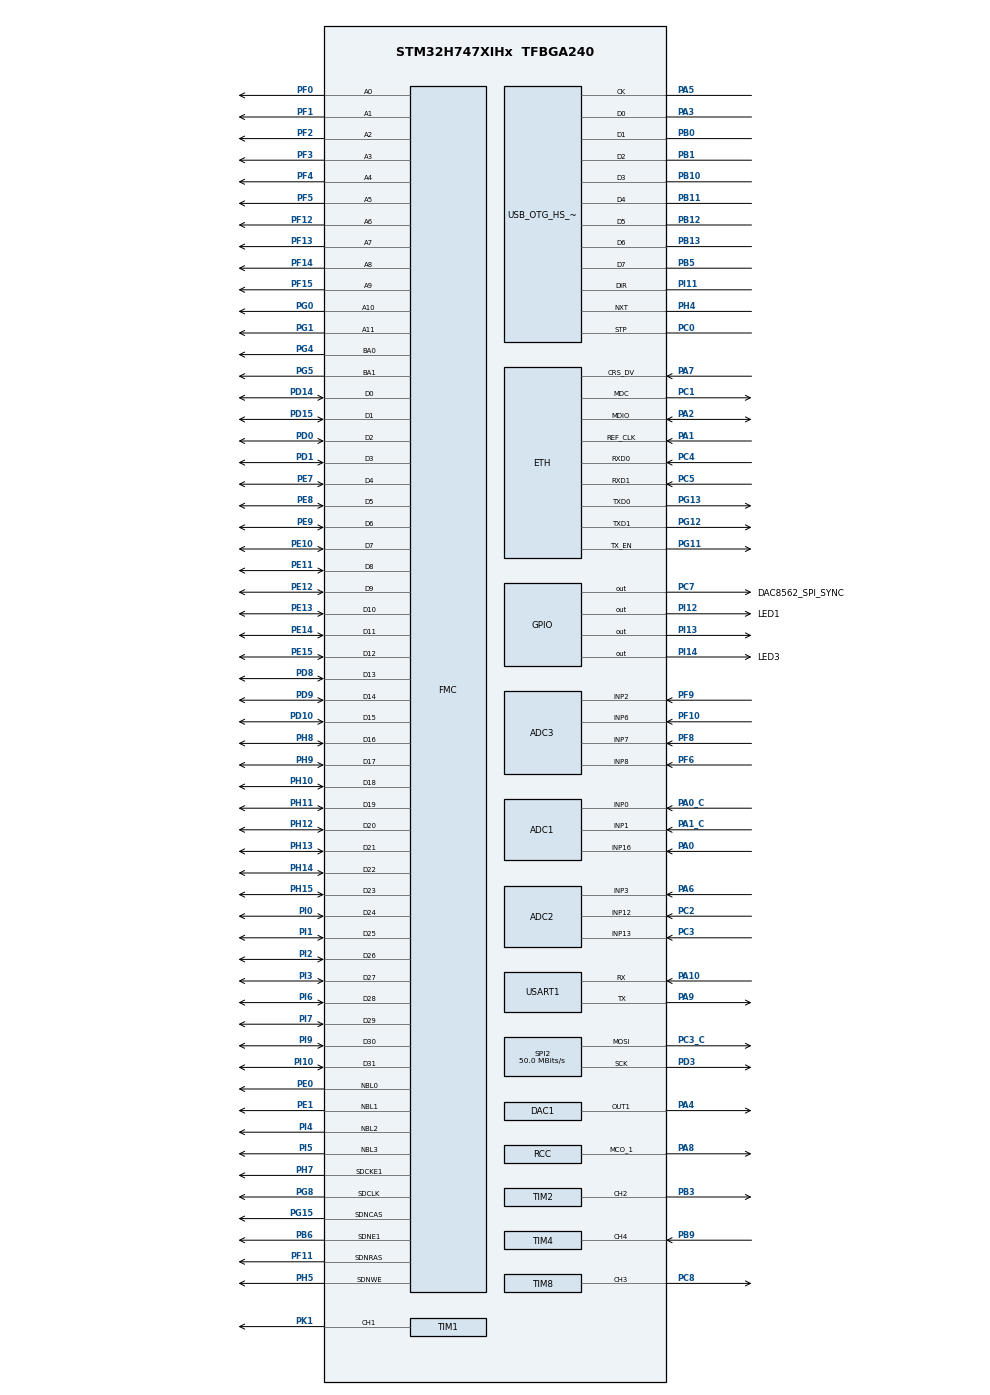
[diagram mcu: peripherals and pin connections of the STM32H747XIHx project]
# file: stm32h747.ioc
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ADC1.Channel-0\#ChannelRegularConversion=ADC_CHANNEL_0
ADC1.Channel-1\#ChannelRegularConversion=ADC_CHANNEL_1
ADC1.Channel-2\#ChannelRegularConversion=ADC_CHANNEL_16
ADC1.ClockPrescaler=ADC_CLOCK_ASYNC_DIV2
ADC1.ClockPrescalerADC3=ADC_CLOCK_ASYNC_DIV2
ADC1.ContinuousConvMode=DISABLE
ADC1.ConversionDataManagement=ADC_CONVERSIONDATA_DMA_CIRCULAR
ADC1.EOCSelection=ADC_EOC_SEQ_CONV
ADC1.ExternalTrigConv=ADC_EXTERNALTRIG_T15_TRGO
ADC1.NbrOfConversion=3
ADC1.NbrOfConversionFlag=1
ADC1.OffsetNumber-0\#ChannelRegularConversion=ADC_OFFSET_NONE
ADC1.OffsetNumber-1\#ChannelRegularConversion=ADC_OFFSET_NONE
ADC1.OffsetNumber-2\#ChannelRegularConversion=ADC_OFFSET_NONE
ADC1.OffsetSignedSaturation-0\#ChannelRegularConversion=DISABLE
ADC1.OffsetSignedSaturation-1\#ChannelRegularConversion=DISABLE
ADC1.OffsetSignedSaturation-2\#ChannelRegularConversion=DISABLE
ADC1.OversamplingMode=DISABLE
ADC1.Rank-0\#ChannelRegularConversion=1
ADC1.Rank-1\#ChannelRegularConversion=2
ADC1.Rank-2\#ChannelRegularConversion=3
ADC1.Ratio=1
ADC1.SamplingTime-0\#ChannelRegularConversion=ADC_SAMPLETIME_32CYCLES_5
ADC1.SamplingTime-1\#ChannelRegularConversion=ADC_SAMPLETIME_32CYCLES_5
ADC1.SamplingTime-2\#ChannelRegularConversion=ADC_SAMPLETIME_32CYCLES_5
ADC1.master=1
ADC2.Channel-0\#ChannelRegularConversion=ADC_CHANNEL_3
ADC2.Channel-1\#ChannelRegularConversion=ADC_CHANNEL_12
ADC2.Channel-2\#ChannelRegularConversion=ADC_CHANNEL_13
ADC2.ClockPrescaler=ADC_CLOCK_ASYNC_DIV2
ADC2.ClockPrescalerADC3=ADC_CLOCK_ASYNC_DIV2
ADC2.ContinuousConvMode=DISABLE
ADC2.ConversionDataManagement=ADC_CONVERSIONDATA_DMA_CIRCULAR
ADC2.EOCSelection=ADC_EOC_SEQ_CONV
ADC2.ExternalTrigConv=ADC_EXTERNALTRIG_T15_TRGO
ADC2.LeftBitShift=ADC_LEFTBITSHIFT_NONE
ADC2.NbrOfConversion=3
ADC2.NbrOfConversionFlag=1
ADC2.OffsetNumber-0\#ChannelRegularConversion=ADC_OFFSET_NONE
ADC2.OffsetNumber-1\#ChannelRegularConversion=ADC_OFFSET_NONE
ADC2.OffsetNumber-2\#ChannelRegularConversion=ADC_OFFSET_NONE
ADC2.OffsetSignedSaturation-0\#ChannelRegularConversion=DISABLE
ADC2.OffsetSignedSaturation-1\#ChannelRegularConversion=DISABLE
ADC2.OffsetSignedSaturation-2\#ChannelRegularConversion=DISABLE
ADC2.OversamplingMode=DISABLE
ADC2.Rank-0\#ChannelRegularConversion=1
ADC2.Rank-1\#ChannelRegularConversion=2
ADC2.Rank-2\#ChannelRegularConversion=3
ADC2.Ratio=1
ADC2.SamplingTime-0\#ChannelRegularConversion=ADC_SAMPLETIME_32CYCLES_5
ADC2.SamplingTime-1\#ChannelRegularConversion=ADC_SAMPLETIME_32CYCLES_5
ADC2.SamplingTime-2\#ChannelRegularConversion=ADC_SAMPLETIME_32CYCLES_5
ADC3.Channel-0\#ChannelRegularConversion=ADC_CHANNEL_2
ADC3.Channel-1\#ChannelRegularConversion=ADC_CHANNEL_6
ADC3.Channel-2\#ChannelRegularConversion=ADC_CHANNEL_7
ADC3.Channel-3\#ChannelRegularConversion=ADC_CHANNEL_8
ADC3.ClockPrescalerADC3=ADC_CLOCK_ASYNC_DIV2
ADC3.ContinuousConvMode=DISABLE
ADC3.ConversionDataManagement=ADC_CONVERSIONDATA_DMA_CIRCULAR
ADC3.EOCSelection=ADC_EOC_SEQ_CONV
ADC3.ExternalTrigConv=ADC_EXTERNALTRIG_T15_TRGO
ADC3.NbrOfConversion=4
ADC3.NbrOfConversionFlag=1
ADC3.OffsetNumber-0\#ChannelRegularConversion=ADC_OFFSET_NONE
ADC3.OffsetNumber-1\#ChannelRegularConversion=ADC_OFFSET_NONE
ADC3.OffsetNumber-2\#ChannelRegularConversion=ADC_OFFSET_NONE
ADC3.OffsetNumber-3\#ChannelRegularConversion=ADC_OFFSET_NONE
ADC3.OffsetSignedSaturation-0\#ChannelRegularConversion=DISABLE
ADC3.OffsetSignedSaturation-1\#ChannelRegularConversion=DISABLE
ADC3.OffsetSignedSaturation-2\#ChannelRegularConversion=DISABLE
ADC3.OffsetSignedSaturation-3\#ChannelRegularConversion=DISABLE
ADC3.OversamplingMode=DISABLE
ADC3.Rank-0\#ChannelRegularConversion=1
ADC3.Rank-1\#ChannelRegularConversion=2
ADC3.Rank-2\#ChannelRegularConversion=3
ADC3.Rank-3\#ChannelRegularConversion=4
ADC3.Ratio=1
ADC3.SamplingTime-0\#ChannelRegularConversion=ADC_SAMPLETIME_32CYCLES_5
ADC3.SamplingTime-1\#ChannelRegularConversion=ADC_SAMPLETIME_32CYCLES_5
ADC3.SamplingTime-2\#ChannelRegularConversion=ADC_SAMPLETIME_32CYCLES_5
ADC3.SamplingTime-3\#ChannelRegularConversion=ADC_SAMPLETIME_32CYCLES_5
CORTEX_M4.MPU_Control=__NULL
CORTEX_M7.AccessPermission-Cortex_Memory_Protection_Unit_Region1_Settings=MPU_REGION_FULL_ACCESS
CORTEX_M7.AccessPermission-Cortex_Memory_Protection_Unit_Region2_Settings=MPU_REGION_FULL_ACCESS
CORTEX_M7.AccessPermission-Cortex_Memory_Protection_Unit_Region3_Settings=MPU_REGION_FULL_ACCESS
CORTEX_M7.AccessPermission-Cortex_Memory_Protection_Unit_Region4_Settings=MPU_REGION_FULL_ACCESS
CORTEX_M7.BaseAddress-Cortex_Memory_Protection_Unit_Region0_Settings=0x0
CORTEX_M7.BaseAddress-Cortex_Memory_Protection_Unit_Region1_Settings=0x030000600
CORTEX_M7.BaseAddress-Cortex_Memory_Protection_Unit_Region2_Settings=0x30000000
CORTEX_M7.BaseAddress-Cortex_Memory_Protection_Unit_Region3_Settings=0x38000000
CORTEX_M7.BaseAddress-Cortex_Memory_Protection_Unit_Region4_Settings=0xD0000000
CORTEX_M7.CPU_DCache=Enabled
CORTEX_M7.CPU_ICache=Enabled
CORTEX_M7.DisableExec-Cortex_Memory_Protection_Unit_Region0_Settings=MPU_INSTRUCTION_ACCESS_DISABLE
CORTEX_M7.DisableExec-Cortex_Memory_Protection_Unit_Region1_Settings=MPU_INSTRUCTION_ACCESS_DISABLE
CORTEX_M7.DisableExec-Cortex_Memory_Protection_Unit_Region2_Settings=MPU_INSTRUCTION_ACCESS_DISABLE
CORTEX_M7.Enable-Cortex_Memory_Protection_Unit_Region0_Settings=MPU_REGION_ENABLE
CORTEX_M7.Enable-Cortex_Memory_Protection_Unit_Region1_Settings=MPU_REGION_ENABLE
CORTEX_M7.Enable-Cortex_Memory_Protection_Unit_Region2_Settings=MPU_REGION_ENABLE
CORTEX_M7.Enable-Cortex_Memory_Protection_Unit_Region3_Settings=MPU_REGION_ENABLE
CORTEX_M7.Enable-Cortex_Memory_Protection_Unit_Region4_Settings=MPU_REGION_ENABLE
CORTEX_M7.IsBufferable-Cortex_Memory_Protection_Unit_Region2_Settings=MPU_ACCESS_BUFFERABLE
CORTEX_M7.IsBufferable-Cortex_Memory_Protection_Unit_Region4_Settings=MPU_ACCESS_BUFFERABLE
CORTEX_M7.IsCacheable-Cortex_Memory_Protection_Unit_Region4_Settings=MPU_ACCESS_CACHEABLE
CORTEX_M7.IsShareable-Cortex_Memory_Protection_Unit_Region0_Settings=MPU_ACCESS_SHAREABLE
CORTEX_M7.IsShareable-Cortex_Memory_Protection_Unit_Region2_Settings=MPU_ACCESS_SHAREABLE
CORTEX_M7.IsShareable-Cortex_Memory_Protection_Unit_Region3_Settings=MPU_ACCESS_SHAREABLE
CORTEX_M7.IsShareable-Cortex_Memory_Protection_Unit_Region4_Settings=MPU_ACCESS_NOT_SHAREABLE
CORTEX_M7.MPU_Control=MPU_PRIVILEGED_DEFAULT
CORTEX_M7.Size-Cortex_Memory_Protection_Unit_Region0_Settings=MPU_REGION_SIZE_4GB
CORTEX_M7.Size-Cortex_Memory_Protection_Unit_Region1_Settings=MPU_REGION_SIZE_128KB
CORTEX_M7.Size-Cortex_Memory_Protection_Unit_Region2_Settings=MPU_REGION_SIZE_512B
CORTEX_M7.Size-Cortex_Memory_Protection_Unit_Region3_Settings=MPU_REGION_SIZE_64KB
CORTEX_M7.Size-Cortex_Memory_Protection_Unit_Region4_Settings=MPU_REGION_SIZE_32MB
CORTEX_M7.SubRegionDisable-Cortex_Memory_Protection_Unit_Region0_Settings=0x87
CORTEX_M7.TypeExtField-Cortex_Memory_Protection_Unit_Region1_Settings=MPU_TEX_LEVEL1
CORTEX_M7.default_mode_Activation=0
CortexM4.IPs=CORTEX_M4\:I,FATFS_M4\:I,FREERTOS_M4\:I,IWDG2\:I,OPENAMP_M4\:I,PDM2PCM_M4\:I,PWR,RCC,RESMGR_UTILITY,SYS_M4\:I,USB_DEVICE_M4\:I,USB_HOST_M4\:I,VREFBUF,WWDG2\:I,GPIO,DMA,BDMA,MDMA,NVIC2\:I,DEBUG
CortexM7.IPs=CORTEX_M7\:I,FATFS_M7\:I,FREERTOS_M7\:I,IWDG1\:I,OPENAMP_M7\:I,PDM2PCM_M7\:I,PWR\:I,RCC\:I,RESMGR_UTILITY\:I,SYS\:I,USB_DEVICE_M7\:I,USB_HOST_M7\:I,VREFBUF\:I,WWDG1\:I,GPIO\:I,DMA\:I,BDMA\:I,MDMA\:I,NVIC1\:I,ADC1\:I,ADC2\:I,ADC3\:I,TIM1\:I,TIM2\:I,DEBUG\:I,TIM6\:I,ETH\:I,USART1\:I,USB_OTG_HS\:I,USB_OTG_HS1\:I,FMC\:I,DAC1\:I,LWIP\:I,MEMORYMAP\:I,TIM3\:I,TIM15\:I,TIM4\:I,TIM8\:I,SPI2\:I
CortexM7.Pins=PC7,PI12,PI13,PI14
DAC1.DAC_Channel-DAC_OUT1=DAC_CHANNEL_1
Dma.ADC1.0.Direction=DMA_PERIPH_TO_MEMORY
Dma.ADC1.0.EventEnable=DISABLE
Dma.ADC1.0.FIFOMode=DMA_FIFOMODE_DISABLE
Dma.ADC1.0.Instance=DMA1_Stream0
Dma.ADC1.0.MemDataAlignment=DMA_MDATAALIGN_HALFWORD
Dma.ADC1.0.MemInc=DMA_MINC_ENABLE
Dma.ADC1.0.Mode=DMA_CIRCULAR
Dma.ADC1.0.PeriphDataAlignment=DMA_PDATAALIGN_HALFWORD
Dma.ADC1.0.PeriphInc=DMA_PINC_DISABLE
Dma.ADC1.0.Polarity=HAL_DMAMUX_REQ_GEN_RISING
Dma.ADC1.0.Priority=DMA_PRIORITY_LOW
Dma.ADC1.0.RequestNumber=1
Dma.ADC1.0.SignalID=NONE
Dma.ADC1.0.SyncEnable=DISABLE
Dma.ADC1.0.SyncPolarity=HAL_DMAMUX_SYNC_NO_EVENT
Dma.ADC1.0.SyncRequestNumber=1
Dma.ADC1.0.SyncSignalID=NONE
Dma.ADC2.1.Direction=DMA_PERIPH_TO_MEMORY
Dma.ADC2.1.EventEnable=DISABLE
Dma.ADC2.1.FIFOMode=DMA_FIFOMODE_DISABLE
Dma.ADC2.1.Instance=DMA2_Stream2
Dma.ADC2.1.MemDataAlignment=DMA_MDATAALIGN_HALFWORD
Dma.ADC2.1.MemInc=DMA_MINC_ENABLE
Dma.ADC2.1.Mode=DMA_CIRCULAR
Dma.ADC2.1.PeriphDataAlignment=DMA_PDATAALIGN_HALFWORD
Dma.ADC2.1.PeriphInc=DMA_PINC_DISABLE
Dma.ADC2.1.Polarity=HAL_DMAMUX_REQ_GEN_RISING
Dma.ADC2.1.Priority=DMA_PRIORITY_LOW
Dma.ADC2.1.RequestNumber=1
Dma.ADC2.1.SignalID=NONE
Dma.ADC2.1.SyncEnable=DISABLE
Dma.ADC2.1.SyncPolarity=HAL_DMAMUX_SYNC_NO_EVENT
Dma.ADC2.1.SyncRequestNumber=1
Dma.ADC2.1.SyncSignalID=NONE
Dma.ADC3.2.Direction=DMA_PERIPH_TO_MEMORY
Dma.ADC3.2.EventEnable=DISABLE
Dma.ADC3.2.FIFOMode=DMA_FIFOMODE_DISABLE
Dma.ADC3.2.Instance=DMA1_Stream2
Dma.ADC3.2.MemDataAlignment=DMA_MDATAALIGN_HALFWORD
Dma.ADC3.2.MemInc=DMA_MINC_ENABLE
Dma.ADC3.2.Mode=DMA_CIRCULAR
Dma.ADC3.2.PeriphDataAlignment=DMA_PDATAALIGN_HALFWORD
Dma.ADC3.2.PeriphInc=DMA_PINC_DISABLE
Dma.ADC3.2.Polarity=HAL_DMAMUX_REQ_GEN_RISING
Dma.ADC3.2.Priority=DMA_PRIORITY_LOW
Dma.ADC3.2.RequestNumber=1
Dma.ADC3.2.SignalID=NONE
Dma.ADC3.2.SyncEnable=DISABLE
Dma.ADC3.2.SyncPolarity=HAL_DMAMUX_SYNC_NO_EVENT
Dma.ADC3.2.SyncRequestNumber=1
Dma.ADC3.2.SyncSignalID=NONE
Dma.Request0=ADC1
Dma.Request1=ADC2
Dma.Request2=ADC3
Dma.Request3=USART1_RX
Dma.Request4=SPI2_TX
Dma.SPI2_TX.4.Direction=DMA_MEMORY_TO_PERIPH
Dma.SPI2_TX.4.EventEnable=DISABLE
Dma.SPI2_TX.4.FIFOMode=DMA_FIFOMODE_DISABLE
Dma.SPI2_TX.4.Instance=DMA1_Stream3
Dma.SPI2_TX.4.MemDataAlignment=DMA_MDATAALIGN_BYTE
Dma.SPI2_TX.4.MemInc=DMA_MINC_ENABLE
Dma.SPI2_TX.4.Mode=DMA_NORMAL
Dma.SPI2_TX.4.PeriphDataAlignment=DMA_PDATAALIGN_BYTE
Dma.SPI2_TX.4.PeriphInc=DMA_PINC_DISABLE
Dma.SPI2_TX.4.Polarity=HAL_DMAMUX_REQ_GEN_RISING
Dma.SPI2_TX.4.Priority=DMA_PRIORITY_LOW
Dma.SPI2_TX.4.RequestNumber=1
Dma.SPI2_TX.4.SignalID=NONE
Dma.SPI2_TX.4.SyncEnable=DISABLE
Dma.SPI2_TX.4.SyncPolarity=HAL_DMAMUX_SYNC_NO_EVENT
Dma.SPI2_TX.4.SyncRequestNumber=1
Dma.SPI2_TX.4.SyncSignalID=NONE
Dma.USART1_RX.3.Direction=DMA_PERIPH_TO_MEMORY
Dma.USART1_RX.3.EventEnable=DISABLE
Dma.USART1_RX.3.FIFOMode=DMA_FIFOMODE_DISABLE
Dma.USART1_RX.3.Instance=DMA1_Stream1
Dma.USART1_RX.3.MemDataAlignment=DMA_MDATAALIGN_BYTE
Dma.USART1_RX.3.MemInc=DMA_MINC_ENABLE
Dma.USART1_RX.3.Mode=DMA_NORMAL
Dma.USART1_RX.3.PeriphDataAlignment=DMA_PDATAALIGN_BYTE
Dma.USART1_RX.3.PeriphInc=DMA_PINC_DISABLE
Dma.USART1_RX.3.Polarity=HAL_DMAMUX_REQ_GEN_RISING
Dma.USART1_RX.3.Priority=DMA_PRIORITY_LOW
Dma.USART1_RX.3.RequestNumber=1
Dma.USART1_RX.3.SignalID=NONE
Dma.USART1_RX.3.SyncEnable=DISABLE
Dma.USART1_RX.3.SyncPolarity=HAL_DMAMUX_SYNC_NO_EVENT
Dma.USART1_RX.3.SyncRequestNumber=1
Dma.USART1_RX.3.SyncSignalID=NONE
ETH.MediaInterface=HAL_ETH_RMII_MODE
ETH.RxBufferAddress=0x30000200
ETH.RxDescAddress=0x30000000
ETH.TxDescAddress=0x30000100
FMC.CASLatency1=FMC_SDRAM_CAS_LATENCY_3
FMC.ColumnBitsNumber1=FMC_SDRAM_COLUMN_BITS_NUM_9
FMC.ExitSelfRefreshDelay1=7
FMC.LoadToActiveDelay1=2
FMC.RCDDelay1=2
FMC.RPDelay1=2
FMC.RPDelay2=2
FMC.ReadBurst1=FMC_SDRAM_RBURST_ENABLE
FMC.ReadBurst2=FMC_SDRAM_RBURST_ENABLE
FMC.RowCycleDelay1=6
FMC.RowCycleDelay2=6
FMC.SDClockPeriod1=FMC_SDRAM_CLOCK_PERIOD_2
FMC.SDClockPeriod2=FMC_SDRAM_CLOCK_PERIOD_2
FMC.SelfRefreshTime1=4
FMC.WriteRecoveryTime1=2
FREERTOS_M7.Tasks01=defaultTask,24,512,StartDefaultTask,Default,NULL,Dynamic,NULL,NULL
FREERTOS_M7.configCHECK_FOR_STACK_OVERFLOW=2
FREERTOS_M7.configENABLE_FPU=1
FREERTOS_M7.configMINIMAL_STACK_SIZE=512
FREERTOS_M7.configTOTAL_HEAP_SIZE=32768
FREERTOS_M7.configUSE_NEWLIB_REENTRANT=1
LWIP.BSP.number=1
LWIP.DEFAULT_THREAD_PRIO=32
LWIP.DEFAULT_THREAD_STACKSIZE=2048
LWIP.LWIP_NETIF_STATUS_CALLBACK=0
LWIP.LWIP_RAM_HEAP_POINTER=0x30000600
LWIP.LWIP_SO_RCVBUF=1
LWIP.MEMP_NUM_LOCALHOSTLIST=0
LWIP.MEMP_NUM_PBUF=24
LWIP.MEMP_NUM_TCP_PCB_LISTEN=4
LWIP.MEMP_NUM_TCP_SEG=32
LWIP.MEM_SIZE=48 * 1024
LWIP.PBUF_POOL_BUFSIZE=1536
LWIP.SO_REUSE=1
LWIP.TCPIP_THREAD_PRIO=32
LWIP.TCPIP_THREAD_STACKSIZE=2048
LWIP.TCP_LISTEN_BACKLOG=1
LWIP.TCP_MSS=1460
LWIP.TCP_SND_BUF=5840
LWIP.TCP_SND_QUEUELEN=16
LWIP.TCP_WND=5840
LWIP.Version=v2.2.1_Cube
LWIP0.BSP.STBoard=false
LWIP0.BSP.api=BSP_COMPONENT_DRIVER
LWIP0.BSP.component=LAN8742
LWIP0.BSP.instance=LAN8742
LWIP0.BSP.name=Driver_PHY
LWIP0.BSP.semaphore=S_LAN8742
LWIP0.BSP.solution=LAN8742
Mcu.Family=STM32H7
Mcu.Name=STM32H747XIHx
Mcu.Package=TFBGA240
NVIC1.DMA1_Stream0_IRQn=true\:5\:0\:false\:false\:true\:true\:false\:true\:true
NVIC1.DMA1_Stream1_IRQn=true\:5\:0\:false\:false\:true\:true\:false\:true\:true
NVIC1.DMA1_Stream2_IRQn=true\:5\:0\:false\:false\:true\:true\:false\:true\:true
NVIC1.DMA1_Stream3_IRQn=true\:5\:0\:false\:false\:true\:true\:false\:true\:true
NVIC1.DMA2_Stream2_IRQn=true\:5\:0\:false\:false\:true\:true\:false\:true\:true
NVIC1.ETH_IRQn=true\:5\:0\:false\:false\:true\:true\:true\:true\:true
NVIC1.OTG_HS_IRQn=true\:5\:0\:false\:false\:true\:true\:true\:true\:true
NVIC1.PriorityGroup=NVIC_PRIORITYGROUP_4
NVIC1.SPI2_IRQn=true\:5\:0\:false\:false\:true\:true\:false\:true\:true
NVIC1.TIM2_IRQn=true\:5\:0\:false\:false\:true\:true\:true\:true\:true
NVIC1.TIM3_IRQn=true\:5\:0\:false\:false\:true\:true\:true\:true\:true
NVIC1.TIM6_DAC_IRQn=true\:15\:0\:false\:false\:true\:false\:false\:true\:true
NVIC1.TimeBase=TIM6_DAC_IRQn
NVIC1.TimeBaseIP=TIM6
NVIC2.PriorityGroup=NVIC_PRIORITYGROUP_4
PA0.Mode=IN16-Single-Ended
PA0.PinAttribute=CortexM7
PA0.Signal=ADC1_INP16
PA0_C.PinAttribute=CortexM7
PA0_C.Signal=ADCx_INP0
PA1.GPIO_Speed_Default_HIGH=GPIO_SPEED_FREQ_VERY_HIGH
PA1.Mode=RMII
PA1.PinAttribute=CortexM7
PA1.Signal=ETH_REF_CLK
PA10.GPIO_Speed=GPIO_SPEED_FREQ_VERY_HIGH
PA10.Mode=Asynchronous
PA10.PinAttribute=CortexM7
PA10.Signal=USART1_RX
PA13\ (JTMS/SWDIO).Mode=Serial_Wire
PA13\ (JTMS/SWDIO).PinAttribute=CortexM7
PA13\ (JTMS/SWDIO).Signal=DEBUG_JTMS-SWDIO
PA14\ (JTCK/SWCLK).Mode=Serial_Wire
PA14\ (JTCK/SWCLK).PinAttribute=CortexM7
PA14\ (JTCK/SWCLK).Signal=DEBUG_JTCK-SWCLK
PA1_C.PinAttribute=CortexM7
PA1_C.Signal=ADCx_INP1
PA2.GPIO_Speed_Default_HIGH=GPIO_SPEED_FREQ_VERY_HIGH
PA2.Mode=RMII
PA2.PinAttribute=CortexM7
PA2.Signal=ETH_MDIO
PA3.Mode=Device_HS
PA3.PinAttribute=CortexM7
PA3.Signal=USB_OTG_HS_ULPI_D0
PA4.PinAttribute=CortexM7
PA4.Signal=COMP_DAC11_group
PA5.Mode=Device_HS
PA5.PinAttribute=CortexM7
PA5.Signal=USB_OTG_HS_ULPI_CK
PA6.PinAttribute=CortexM7
PA6.Signal=ADCx_INP3
PA7.GPIO_Speed_Default_HIGH=GPIO_SPEED_FREQ_VERY_HIGH
PA7.Mode=RMII
PA7.PinAttribute=CortexM7
PA7.Signal=ETH_CRS_DV
PA8.Mode=Clock-out-1
PA8.PinAttribute=Free
PA8.Signal=RCC_MCO_1
PA9.GPIO_Speed=GPIO_SPEED_FREQ_VERY_HIGH
PA9.Mode=Asynchronous
PA9.PinAttribute=CortexM7
PA9.Signal=USART1_TX
PB0.Mode=Device_HS
PB0.PinAttribute=CortexM7
PB0.Signal=USB_OTG_HS_ULPI_D1
PB1.Mode=Device_HS
PB1.PinAttribute=CortexM7
PB1.Signal=USB_OTG_HS_ULPI_D2
PB10.Mode=Device_HS
PB10.PinAttribute=CortexM7
PB10.Signal=USB_OTG_HS_ULPI_D3
PB11.Mode=Device_HS
PB11.PinAttribute=CortexM7
PB11.Signal=USB_OTG_HS_ULPI_D4
PB12.Mode=Device_HS
PB12.PinAttribute=CortexM7
PB12.Signal=USB_OTG_HS_ULPI_D5
PB13.Mode=Device_HS
PB13.PinAttribute=CortexM7
PB13.Signal=USB_OTG_HS_ULPI_D6
PB3\ (JTDO/TRACESWO).PinAttribute=CortexM7
PB3\ (JTDO/TRACESWO).Signal=S_TIM2_CH2
PB5.Mode=Device_HS
PB5.PinAttribute=CortexM7
PB5.Signal=USB_OTG_HS_ULPI_D7
PB6.Mode=SdramChipSelect2_1
PB6.PinAttribute=CortexM7
PB6.Signal=FMC_SDNE1
PB9.PinAttribute=CortexM7
PB9.Signal=S_TIM4_CH4
PC0.Mode=Device_HS
PC0.PinAttribute=CortexM7
PC0.Signal=USB_OTG_HS_ULPI_STP
PC1.GPIO_Speed_Default_HIGH=GPIO_SPEED_FREQ_VERY_HIGH
PC1.Mode=RMII
PC1.PinAttribute=CortexM7
PC1.Signal=ETH_MDC
PC2.PinAttribute=CortexM7
PC2.Signal=ADCx_INP12
PC3.PinAttribute=CortexM7
PC3.Signal=ADCx_INP13
PC3_C.GPIO_Speed=GPIO_SPEED_FREQ_VERY_HIGH
PC3_C.Mode=TX_Only_Simplex_Unidirect_Master
PC3_C.PinAttribute=CortexM7
PC3_C.Signal=SPI2_MOSI
PC4.GPIO_Speed_Default_HIGH=GPIO_SPEED_FREQ_VERY_HIGH
PC4.Mode=RMII
PC4.PinAttribute=CortexM7
PC4.Signal=ETH_RXD0
PC5.GPIO_Speed_Default_HIGH=GPIO_SPEED_FREQ_VERY_HIGH
PC5.Mode=RMII
PC5.PinAttribute=CortexM7
PC5.Signal=ETH_RXD1
PC7.GPIO_Label=DAC8562_SPI_SYNC
PC7.GPIO_Speed=GPIO_SPEED_FREQ_VERY_HIGH
PC7.PinAttribute=CortexM7
PC7.Signal=GPIO_Output
PC8.PinAttribute=CortexM7
PC8.Signal=S_TIM8_CH3
PD0.PinAttribute=CortexM7
PD0.Signal=FMC_D2_DA2
PD1.PinAttribute=CortexM7
PD1.Signal=FMC_D3_DA3
PD10.PinAttribute=CortexM7
PD10.Signal=FMC_D15_DA15
PD14.PinAttribute=CortexM7
PD14.Signal=FMC_D0_DA0
PD15.PinAttribute=CortexM7
PD15.Signal=FMC_D1_DA1
PD3.GPIO_Speed=GPIO_SPEED_FREQ_VERY_HIGH
PD3.Mode=TX_Only_Simplex_Unidirect_Master
PD3.PinAttribute=CortexM7
PD3.Signal=SPI2_SCK
PD8.PinAttribute=CortexM7
PD8.Signal=FMC_D13_DA13
PD9.PinAttribute=CortexM7
PD9.Signal=FMC_D14_DA14
PE0.PinAttribute=CortexM7
PE0.Signal=FMC_NBL0
PE1.PinAttribute=CortexM7
PE1.Signal=FMC_NBL1
PE10.PinAttribute=CortexM7
PE10.Signal=FMC_D7_DA7
PE11.PinAttribute=CortexM7
PE11.Signal=FMC_D8_DA8
PE12.PinAttribute=CortexM7
PE12.Signal=FMC_D9_DA9
PE13.PinAttribute=CortexM7
PE13.Signal=FMC_D10_DA10
PE14.PinAttribute=CortexM7
PE14.Signal=FMC_D11_DA11
PE15.PinAttribute=CortexM7
PE15.Signal=FMC_D12_DA12
PE7.PinAttribute=CortexM7
PE7.Signal=FMC_D4_DA4
PE8.PinAttribute=CortexM7
PE8.Signal=FMC_D5_DA5
PE9.PinAttribute=CortexM7
PE9.Signal=FMC_D6_DA6
PF0.PinAttribute=CortexM7
PF0.Signal=FMC_A0
PF1.PinAttribute=CortexM7
PF1.Signal=FMC_A1
PF10.Mode=IN6-Single-Ended
PF10.PinAttribute=CortexM7
PF10.Signal=ADC3_INP6
PF11.PinAttribute=CortexM7
PF11.Signal=FMC_SDNRAS
PF12.PinAttribute=CortexM7
PF12.Signal=FMC_A6
PF13.PinAttribute=CortexM7
PF13.Signal=FMC_A7
PF14.PinAttribute=CortexM7
PF14.Signal=FMC_A8
PF15.PinAttribute=CortexM7
PF15.Signal=FMC_A9
PF2.PinAttribute=CortexM7
PF2.Signal=FMC_A2
PF3.PinAttribute=CortexM7
PF3.Signal=FMC_A3
PF4.PinAttribute=CortexM7
PF4.Signal=FMC_A4
PF5.PinAttribute=CortexM7
PF5.Signal=FMC_A5
PF6.Mode=IN8-Single-Ended
PF6.PinAttribute=CortexM7
PF6.Signal=ADC3_INP8
PF8.Mode=IN7-Single-Ended
PF8.PinAttribute=CortexM7
PF8.Signal=ADC3_INP7
PF9.Mode=IN2-Single-Ended
PF9.PinAttribute=CortexM7
PF9.Signal=ADC3_INP2
PG0.PinAttribute=CortexM7
PG0.Signal=FMC_A10
PG1.PinAttribute=CortexM7
PG1.Signal=FMC_A11
PG11.GPIO_Speed_Default_HIGH=GPIO_SPEED_FREQ_VERY_HIGH
PG11.Mode=RMII
PG11.PinAttribute=CortexM7
PG11.Signal=ETH_TX_EN
PG12.GPIO_Speed_Default_HIGH=GPIO_SPEED_FREQ_VERY_HIGH
PG12.Mode=RMII
PG12.PinAttribute=CortexM7
PG12.Signal=ETH_TXD1
PG13.GPIO_Speed_Default_HIGH=GPIO_SPEED_FREQ_VERY_HIGH
PG13.Mode=RMII
PG13.PinAttribute=CortexM7
PG13.Signal=ETH_TXD0
PG15.PinAttribute=CortexM7
PG15.Signal=FMC_SDNCAS
PG4.PinAttribute=CortexM7
PG4.Signal=FMC_A14_BA0
PG5.PinAttribute=CortexM7
PG5.Signal=FMC_A15_BA1
PG8.PinAttribute=CortexM7
PG8.Signal=FMC_SDCLK
PH0-OSC_IN\ (PH0).Mode=HSE-External-Oscillator
PH0-OSC_IN\ (PH0).PinAttribute=Free
PH0-OSC_IN\ (PH0).Signal=RCC_OSC_IN
PH1-OSC_OUT\ (PH1).Mode=HSE-External-Oscillator
PH1-OSC_OUT\ (PH1).PinAttribute=Free
PH1-OSC_OUT\ (PH1).Signal=RCC_OSC_OUT
PH10.PinAttribute=CortexM7
PH10.Signal=FMC_D18
PH11.PinAttribute=CortexM7
PH11.Signal=FMC_D19
PH12.PinAttribute=CortexM7
PH12.Signal=FMC_D20
PH13.PinAttribute=CortexM7
PH13.Signal=FMC_D21
PH14.PinAttribute=CortexM7
PH14.Signal=FMC_D22
PH15.PinAttribute=CortexM7
PH15.Signal=FMC_D23
PH4.Mode=Device_HS
PH4.PinAttribute=CortexM7
PH4.Signal=USB_OTG_HS_ULPI_NXT
PH5.PinAttribute=CortexM7
PH5.Signal=FMC_SDNWE
PH7.Mode=SdramChipSelect2_1
PH7.PinAttribute=CortexM7
PH7.Signal=FMC_SDCKE1
PH8.PinAttribute=CortexM7
PH8.Signal=FMC_D16
PH9.PinAttribute=CortexM7
PH9.Signal=FMC_D17
PI0.PinAttribute=CortexM7
PI0.Signal=FMC_D24
PI1.PinAttribute=CortexM7
PI1.Signal=FMC_D25
PI10.PinAttribute=CortexM7
PI10.Signal=FMC_D31
PI11.Mode=Device_HS
PI11.PinAttribute=CortexM7
PI11.Signal=USB_OTG_HS_ULPI_DIR
PI12.GPIO_Label=LED1
PI12.PinAttribute=CortexM7
PI12.Signal=GPIO_Output
PI13.PinAttribute=CortexM7
PI13.Signal=GPIO_Output
PI14.GPIO_Label=LED3
PI14.PinAttribute=CortexM7
PI14.Signal=GPIO_Output
PI2.PinAttribute=CortexM7
PI2.Signal=FMC_D26
PI3.PinAttribute=CortexM7
PI3.Signal=FMC_D27
PI4.PinAttribute=CortexM7
PI4.Signal=FMC_NBL2
PI5.PinAttribute=CortexM7
PI5.Signal=FMC_NBL3
PI6.PinAttribute=CortexM7
PI6.Signal=FMC_D28
PI7.PinAttribute=CortexM7
PI7.Signal=FMC_D29
PI9.PinAttribute=CortexM7
PI9.Signal=FMC_D30
PK1.GPIO_Speed=GPIO_SPEED_FREQ_VERY_HIGH
PK1.PinAttribute=CortexM7
PK1.Signal=S_TIM1_CH1
ProjectManager.HeapSize=M4-0x200,M7-0x200
ProjectManager.StackSize=M4-0x1000,M7-0x1000
ProjectManager.TargetToolchain=CMake
RCC.ADCCLockSelection=RCC_ADCCLKSOURCE_PLL3
RCC.ADCFreq_Value=100000000
RCC.APB1Freq_Value=100000000
RCC.APB2Freq_Value=100000000
RCC.APB3Freq_Value=100000000
RCC.APB4Freq_Value=100000000
RCC.CortexFreq_Value=400000000
RCC.D1PPRE=RCC_APB3_DIV2
RCC.D2PPRE1=RCC_APB1_DIV2
RCC.D2PPRE2=RCC_APB2_DIV2
RCC.D3PPRE=RCC_APB4_DIV2
RCC.DIVM1=2
RCC.DIVM2=25
RCC.DIVM3=2
RCC.DIVN1=64
RCC.DIVN2=150
RCC.DIVN3=32
RCC.DIVQ3=4
RCC.DIVR3=4
RCC.HCLKFreq_Value=200000000
RCC.HPRE=RCC_HCLK_DIV2
RCC.PLL2_VCO_SEL-AdvancedSettings=RCC_PLL2VCOWIDE
RCC.PLL3FRACN=0
RCC.PLLFRACN=0
RCC.PLLSourceVirtual=RCC_PLLSOURCE_HSE
RCC.SPI123CLockSelection=RCC_SPI123CLKSOURCE_PLL3
RCC.SYSCLKFreq_VALUE=400000000
RCC.SYSCLKSource=RCC_SYSCLKSOURCE_PLLCLK
RCC.Spi45ClockSelection=RCC_SPI45CLKSOURCE_PLL3
RCC.SupplySource=PWR_DIRECT_SMPS_SUPPLY
RCC.USBCLockSelection=RCC_USBCLKSOURCE_HSI48
RCC.USBFreq_Value=48000000
SH.ADCx_INP0.0=ADC1_INP0,IN0-Single-Ended
SH.ADCx_INP1.0=ADC1_INP1,IN1-Single-Ended
SH.ADCx_INP12.0=ADC2_INP12,IN12-Single-Ended
SH.ADCx_INP13.0=ADC2_INP13,IN13-Single-Ended
SH.ADCx_INP3.0=ADC2_INP3,IN3-Single-Ended
SH.COMP_DAC11_group.0=DAC1_OUT1,DAC_OUT1
SH.FMC_A0.0=FMC_A0,12b-sda1
SH.FMC_A1.0=FMC_A1,12b-sda1
SH.FMC_A10.0=FMC_A10,12b-sda1
SH.FMC_A11.0=FMC_A11,12b-sda1
SH.FMC_A14_BA0.0=FMC_BA0,FourSdramBanks1
SH.FMC_A15_BA1.0=FMC_BA1,FourSdramBanks1
SH.FMC_A2.0=FMC_A2,12b-sda1
SH.FMC_A3.0=FMC_A3,12b-sda1
SH.FMC_A4.0=FMC_A4,12b-sda1
SH.FMC_A5.0=FMC_A5,12b-sda1
SH.FMC_A6.0=FMC_A6,12b-sda1
SH.FMC_A7.0=FMC_A7,12b-sda1
SH.FMC_A8.0=FMC_A8,12b-sda1
SH.FMC_A9.0=FMC_A9,12b-sda1
SH.FMC_D0_DA0.0=FMC_D0,sd-32b-d1
SH.FMC_D10_DA10.0=FMC_D10,sd-32b-d1
SH.FMC_D11_DA11.0=FMC_D11,sd-32b-d1
SH.FMC_D12_DA12.0=FMC_D12,sd-32b-d1
SH.FMC_D13_DA13.0=FMC_D13,sd-32b-d1
SH.FMC_D14_DA14.0=FMC_D14,sd-32b-d1
SH.FMC_D15_DA15.0=FMC_D15,sd-32b-d1
SH.FMC_D16.0=FMC_D16,sd-32b-d1
SH.FMC_D17.0=FMC_D17,sd-32b-d1
SH.FMC_D18.0=FMC_D18,sd-32b-d1
SH.FMC_D19.0=FMC_D19,sd-32b-d1
SH.FMC_D1_DA1.0=FMC_D1,sd-32b-d1
SH.FMC_D20.0=FMC_D20,sd-32b-d1
SH.FMC_D21.0=FMC_D21,sd-32b-d1
SH.FMC_D22.0=FMC_D22,sd-32b-d1
SH.FMC_D23.0=FMC_D23,sd-32b-d1
SH.FMC_D24.0=FMC_D24,sd-32b-d1
SH.FMC_D25.0=FMC_D25,sd-32b-d1
SH.FMC_D26.0=FMC_D26,sd-32b-d1
SH.FMC_D27.0=FMC_D27,sd-32b-d1
SH.FMC_D28.0=FMC_D28,sd-32b-d1
SH.FMC_D29.0=FMC_D29,sd-32b-d1
SH.FMC_D2_DA2.0=FMC_D2,sd-32b-d1
SH.FMC_D30.0=FMC_D30,sd-32b-d1
SH.FMC_D31.0=FMC_D31,sd-32b-d1
SH.FMC_D3_DA3.0=FMC_D3,sd-32b-d1
SH.FMC_D4_DA4.0=FMC_D4,sd-32b-d1
SH.FMC_D5_DA5.0=FMC_D5,sd-32b-d1
SH.FMC_D6_DA6.0=FMC_D6,sd-32b-d1
SH.FMC_D7_DA7.0=FMC_D7,sd-32b-d1
SH.FMC_D8_DA8.0=FMC_D8,sd-32b-d1
SH.FMC_D9_DA9.0=FMC_D9,sd-32b-d1
SH.FMC_NBL0.0=FMC_NBL0,Sd4ByteEnable1
SH.FMC_NBL1.0=FMC_NBL1,Sd4ByteEnable1
SH.FMC_NBL2.0=FMC_NBL2,Sd4ByteEnable1
SH.FMC_NBL3.0=FMC_NBL3,Sd4ByteEnable1
SH.FMC_SDCLK.0=FMC_SDCLK,12b-sda1
SH.FMC_SDNCAS.0=FMC_SDNCAS,12b-sda1
SH.FMC_SDNRAS.0=FMC_SDNRAS,12b-sda1
SH.FMC_SDNWE.0=FMC_SDNWE,12b-sda1
SH.S_TIM1_CH1.0=TIM1_CH1,PWM Generation1 CH1
SH.S_TIM2_CH2.0=TIM2_CH2,PWM Generation2 CH2
SH.S_TIM4_CH4.0=TIM4_CH4,Input_Capture4_from_TI4
SH.S_TIM8_CH3.0=TIM8_CH3,PWM Generation3 CH3
SPI2.BaudRatePrescaler=SPI_BAUDRATEPRESCALER_4
SPI2.CLKPhase=SPI_PHASE_2EDGE
SPI2.CalculateBaudRate=50.0 MBits/s
SPI2.DataSize=SPI_DATASIZE_8BIT
SPI2.Direction=SPI_DIRECTION_2LINES_TXONLY
SPI2.Mode=SPI_MODE_MASTER
SPI2.VirtualType=VM_MASTER
SYS.userName=SYS_M7
TIM1.Channel-PWM\ Generation1\ CH1=TIM_CHANNEL_1
TIM1.OCMode_PWM-PWM\ Generation1\ CH1=TIM_OCMODE_PWM2
TIM1.Period=10
TIM1.Prescaler=48000-1
TIM1.Pulse-PWM\ Generation1\ CH1=1
TIM15.AutoReloadPreload=TIM_AUTORELOAD_PRELOAD_ENABLE
TIM15.Period=13019
TIM15.TIM_MasterOutputTrigger=TIM_TRGO_UPDATE
TIM2.Channel-PWM\ Generation2\ CH2=TIM_CHANNEL_2
TIM2.Prescaler=100-1
TIM3.Period=15625
TIM3.Prescaler=0
TIM4.Channel-Input_Capture4_from_TI4=TIM_CHANNEL_4
TIM8.Channel-PWM\ Generation3\ CH3=TIM_CHANNEL_3
USART1.VirtualMode-Asynchronous=VM_ASYNC
USB_OTG_HS.Sof_enable-Device_HS=ENABLE
USB_OTG_HS.VirtualMode-Device_HS=Device_HS
USB_OTG_HS.dma_enable-Device_HS=ENABLE
VP_FREERTOS_M7_VS_CMSIS_V2.Mode=CMSIS_V2
VP_LWIP_VS_Enabled.Mode=Enabled
VP_MEMORYMAP_VS_MEMORYMAP.Mode=CurAppReg
VP_SYS_M4_VS_Systick.Mode=SysTick
VP_SYS_VS_tim6.Mode=TIM6
VP_TIM15_VS_ClockSourceINT.Mode=Internal
VP_TIM1_VS_ClockSourceINT.Mode=Internal
VP_TIM2_VS_ClockSourceINT.Mode=Internal
VP_TIM3_VS_ClockSourceINT.Mode=Internal
board=custom

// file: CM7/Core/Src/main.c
/* USER CODE BEGIN Header */
/**
  ******************************************************************************
  * @file           : main.c
  * @brief          : Main program body
  ******************************************************************************
  * @attention
  *
  * Copyright (c) 2026 STMicroelectronics.
  * All rights reserved.
  *
  * This software is licensed under terms that can be found in the LICENSE file
  * in the root directory of this software component.
  * If no LICENSE file comes with this software, it is provided AS-IS.
  *
  ******************************************************************************
  */
/* USER CODE END Header */
#include "main.h"
#include "FreeRTOS.h"
#include "cmsis_os2.h"
#include "lwip.h"

/* USER CODE BEGIN Includes */
#include "ap.h"
#include "stm32h747xx.h"
#include "IEC61850_SV.h"
/* USER CODE END Includes */

/* USER CODE BEGIN PD */

/* DUAL_CORE_BOOT_SYNC_SEQUENCE: Define for dual core boot synchronization    */
/*                             demonstration code based on hardware semaphore */
/* This define is present in both CM7/CM4 projects                            */
/* To comment when developping/debugging on a single core                     */
//#define DUAL_CORE_BOOT_SYNC_SEQUENCE

#if defined(DUAL_CORE_BOOT_SYNC_SEQUENCE)
#ifndef HSEM_ID_0
#define HSEM_ID_0 (0U) /* HW semaphore 0*/
#endif
#endif /* DUAL_CORE_BOOT_SYNC_SEQUENCE */

/* USER CODE END PD */

ADC_HandleTypeDef hadc1;
ADC_HandleTypeDef hadc2;
ADC_HandleTypeDef hadc3;
DMA_HandleTypeDef hdma_adc1;
DMA_HandleTypeDef hdma_adc2;
DMA_HandleTypeDef hdma_adc3;

DAC_HandleTypeDef hdac1;

SPI_HandleTypeDef hspi2;
DMA_HandleTypeDef hdma_spi2_tx;

TIM_HandleTypeDef htim1;
TIM_HandleTypeDef htim2;
TIM_HandleTypeDef htim3;
TIM_HandleTypeDef htim4;
TIM_HandleTypeDef htim8;
TIM_HandleTypeDef htim15;

UART_HandleTypeDef huart1;
DMA_HandleTypeDef hdma_usart1_rx;

PCD_HandleTypeDef hpcd_USB_OTG_HS;

SDRAM_HandleTypeDef hsdram1;

/* Definitions for defaultTask */
osThreadId_t defaultTaskHandle;
const osThreadAttr_t defaultTask_attributes = {
  .name = "defaultTask",
  .stack_size = 512 * 4,
  .priority = (osPriority_t) osPriorityNormal,
};
/* USER CODE BEGIN PV */
// IEC61850 Sampled Values task attributes
/* Definitions for IEC61850_SV */
osThreadId_t IEC61850_SVHandle;
const osThreadAttr_t IEC61850_SV_attributes = {
  .name = "IEC61850_SV",
  .stack_size = 512 * 4,
  .priority = (osPriority_t) osPriorityAboveNormal,
};

/* USER CODE END PV */

void SystemClock_Config(void);
void PeriphCommonClock_Config(void);
static void MPU_Config(void);
static void MX_GPIO_Init(void);
static void MX_DMA_Init(void);
static void MX_TIM1_Init(void);
static void MX_TIM2_Init(void);
static void MX_ADC1_Init(void);
static void MX_ADC2_Init(void);
static void MX_ADC3_Init(void);
static void MX_FMC_Init(void);
static void MX_USART1_UART_Init(void);
static void MX_USB_OTG_HS_PCD_Init(void);
static void MX_DAC1_Init(void);
static void MX_TIM3_Init(void);
static void MX_TIM15_Init(void);
static void MX_TIM4_Init(void);
static void MX_TIM8_Init(void);
static void MX_SPI2_Init(void);
void StartDefaultTask(void *argument);

int main(void)
{

/* USER CODE BEGIN Boot_Mode_Sequence_0 */
#if defined(DUAL_CORE_BOOT_SYNC_SEQUENCE)
  int32_t timeout;
#endif /* DUAL_CORE_BOOT_SYNC_SEQUENCE */
/* USER CODE END Boot_Mode_Sequence_0 */

  /* MPU Configuration--------------------------------------------------------*/
  MPU_Config();

  /* Enable the CPU Cache */

  /* Enable I-Cache---------------------------------------------------------*/
  SCB_EnableICache();

  /* Enable D-Cache---------------------------------------------------------*/
  SCB_EnableDCache();

/* USER CODE BEGIN Boot_Mode_Sequence_1 */
// #if defined(DUAL_CORE_BOOT_SYNC_SEQUENCE)
//   /* Wait until CPU2 boots and enters in stop mode or timeout*/
//   timeout = 0xFFFF;
//   while((__HAL_RCC_GET_FLAG(RCC_FLAG_D2CKRDY) != RESET) && (timeout-- > 0));
//   if ( timeout < 0 )
//   {
//   Error_Handler();
//   }
// #endif /* DUAL_CORE_BOOT_SYNC_SEQUENCE */
/* USER CODE END Boot_Mode_Sequence_1 */
  /* MCU Configuration--------------------------------------------------------*/

  /* Reset of all peripherals, Initializes the Flash interface and the Systick. */
  HAL_Init();

  /* Configure the system clock */
  SystemClock_Config();

  /* Configure the peripherals common clocks */
  PeriphCommonClock_Config();
/* USER CODE BEGIN Boot_Mode_Sequence_2 */
#if defined(DUAL_CORE_BOOT_SYNC_SEQUENCE)
/* When system initialization is finished, Cortex-M7 will release Cortex-M4 by means of
HSEM notification */
/*HW semaphore Clock enable*/
__HAL_RCC_HSEM_CLK_ENABLE();
/*Take HSEM */
HAL_HSEM_FastTake(HSEM_ID_0);
/*Release HSEM in order to notify the CPU2(CM4)*/
HAL_HSEM_Release(HSEM_ID_0,0);
/* wait until CPU2 wakes up from stop mode */
timeout = 0xFFFF;
while((__HAL_RCC_GET_FLAG(RCC_FLAG_D2CKRDY) == RESET) && (timeout-- > 0));
if ( timeout < 0 )
{
Error_Handler();
}
#endif /* DUAL_CORE_BOOT_SYNC_SEQUENCE */
/* USER CODE END Boot_Mode_Sequence_2 */

  /* Initialize all configured peripherals */
  MX_GPIO_Init();
  MX_DMA_Init();
  MX_TIM1_Init();
  MX_TIM2_Init();
  MX_ADC1_Init();
  MX_ADC2_Init();
  MX_ADC3_Init();
  MX_FMC_Init();
  MX_USART1_UART_Init();
  MX_USB_OTG_HS_PCD_Init();
  MX_DAC1_Init();
  MX_TIM3_Init();
  MX_TIM15_Init();
  MX_TIM4_Init();
  MX_TIM8_Init();
  MX_SPI2_Init();
  /* USER CODE BEGIN 2 */

  hwInit();
  apInit();
  //apMain();

  /* USER CODE END 2 */

  /* Init scheduler */
  osKernelInitialize();

  /* Create the thread(s) */
  /* creation of defaultTask */
  defaultTaskHandle = osThreadNew(StartDefaultTask, NULL, &defaultTask_attributes);

  /* Start scheduler */
  osKernelStart();

  /* We should never get here as control is now taken by the scheduler */

  /* Infinite loop */
  while (1)
  {

  }
}

void SystemClock_Config(void)
{
  RCC_OscInitTypeDef RCC_OscInitStruct = {0};
  RCC_ClkInitTypeDef RCC_ClkInitStruct = {0};

  /** Supply configuration update enable
  */
  HAL_PWREx_ConfigSupply(PWR_DIRECT_SMPS_SUPPLY);

  /** Configure the main internal regulator output voltage
  */
  __HAL_PWR_VOLTAGESCALING_CONFIG(PWR_REGULATOR_VOLTAGE_SCALE1);

  while(!__HAL_PWR_GET_FLAG(PWR_FLAG_VOSRDY)) {}

  /** Initializes the RCC Oscillators according to the specified parameters
  * in the RCC_OscInitTypeDef structure.
  */
  RCC_OscInitStruct.OscillatorType = RCC_OSCILLATORTYPE_HSI48|RCC_OSCILLATORTYPE_HSI
                              |RCC_OSCILLATORTYPE_HSE;
  RCC_OscInitStruct.HSEState = RCC_HSE_ON;
  RCC_OscInitStruct.HSIState = RCC_HSI_DIV1;
  RCC_OscInitStruct.HSICalibrationValue = RCC_HSICALIBRATION_DEFAULT;
  RCC_OscInitStruct.HSI48State = RCC_HSI48_ON;
  RCC_OscInitStruct.PLL.PLLState = RCC_PLL_ON;
  RCC_OscInitStruct.PLL.PLLSource = RCC_PLLSOURCE_HSE;
  RCC_OscInitStruct.PLL.PLLM = 2;
  RCC_OscInitStruct.PLL.PLLN = 64;
  RCC_OscInitStruct.PLL.PLLP = 2;
  RCC_OscInitStruct.PLL.PLLQ = 2;
  RCC_OscInitStruct.PLL.PLLR = 2;
  RCC_OscInitStruct.PLL.PLLRGE = RCC_PLL1VCIRANGE_3;
  RCC_OscInitStruct.PLL.PLLVCOSEL = RCC_PLL1VCOWIDE;
  RCC_OscInitStruct.PLL.PLLFRACN = 0;
  if (HAL_RCC_OscConfig(&RCC_OscInitStruct) != HAL_OK)
  {
    Error_Handler();
  }

  /** Initializes the CPU, AHB and APB buses clocks
  */
  RCC_ClkInitStruct.ClockType = RCC_CLOCKTYPE_HCLK|RCC_CLOCKTYPE_SYSCLK
                              |RCC_CLOCKTYPE_PCLK1|RCC_CLOCKTYPE_PCLK2
                              |RCC_CLOCKTYPE_D3PCLK1|RCC_CLOCKTYPE_D1PCLK1;
  RCC_ClkInitStruct.SYSCLKSource = RCC_SYSCLKSOURCE_PLLCLK;
  RCC_ClkInitStruct.SYSCLKDivider = RCC_SYSCLK_DIV1;
  RCC_ClkInitStruct.AHBCLKDivider = RCC_HCLK_DIV2;
  RCC_ClkInitStruct.APB3CLKDivider = RCC_APB3_DIV2;
  RCC_ClkInitStruct.APB1CLKDivider = RCC_APB1_DIV2;
  RCC_ClkInitStruct.APB2CLKDivider = RCC_APB2_DIV2;
  RCC_ClkInitStruct.APB4CLKDivider = RCC_APB4_DIV2;

  if (HAL_RCC_ClockConfig(&RCC_ClkInitStruct, FLASH_LATENCY_2) != HAL_OK)
  {
    Error_Handler();
  }
  HAL_RCC_MCOConfig(RCC_MCO1, RCC_MCO1SOURCE_HSI, RCC_MCODIV_1);
}

void PeriphCommonClock_Config(void)
{
  RCC_PeriphCLKInitTypeDef PeriphClkInitStruct = {0};

  /** Initializes the peripherals clock
  */
  PeriphClkInitStruct.PeriphClockSelection = RCC_PERIPHCLK_ADC|RCC_PERIPHCLK_SPI2;
  PeriphClkInitStruct.PLL3.PLL3M = 2;
  PeriphClkInitStruct.PLL3.PLL3N = 32;
  PeriphClkInitStruct.PLL3.PLL3P = 2;
  PeriphClkInitStruct.PLL3.PLL3Q = 4;
  PeriphClkInitStruct.PLL3.PLL3R = 4;
  PeriphClkInitStruct.PLL3.PLL3RGE = RCC_PLL3VCIRANGE_3;
  PeriphClkInitStruct.PLL3.PLL3VCOSEL = RCC_PLL3VCOWIDE;
  PeriphClkInitStruct.PLL3.PLL3FRACN = 0;
  PeriphClkInitStruct.Spi123ClockSelection = RCC_SPI123CLKSOURCE_PLL3;
  PeriphClkInitStruct.AdcClockSelection = RCC_ADCCLKSOURCE_PLL3;
  if (HAL_RCCEx_PeriphCLKConfig(&PeriphClkInitStruct) != HAL_OK)
  {
    Error_Handler();
  }
}

static void MX_ADC1_Init(void)
{

  ADC_MultiModeTypeDef multimode = {0};
  ADC_ChannelConfTypeDef sConfig = {0};

  /** Common config
  */
  hadc1.Instance = ADC1;
  hadc1.Init.ClockPrescaler = ADC_CLOCK_ASYNC_DIV2;
  hadc1.Init.Resolution = ADC_RESOLUTION_16B;
  hadc1.Init.ScanConvMode = ADC_SCAN_ENABLE;
  hadc1.Init.EOCSelection = ADC_EOC_SEQ_CONV;
  hadc1.Init.LowPowerAutoWait = DISABLE;
  hadc1.Init.ContinuousConvMode = DISABLE;
  hadc1.Init.NbrOfConversion = 3;
  hadc1.Init.DiscontinuousConvMode = DISABLE;
  hadc1.Init.ExternalTrigConv = ADC_EXTERNALTRIG_T15_TRGO;
  hadc1.Init.ExternalTrigConvEdge = ADC_EXTERNALTRIGCONVEDGE_RISING;
  hadc1.Init.ConversionDataManagement = ADC_CONVERSIONDATA_DMA_CIRCULAR;
  hadc1.Init.Overrun = ADC_OVR_DATA_PRESERVED;
  hadc1.Init.LeftBitShift = ADC_LEFTBITSHIFT_NONE;
  hadc1.Init.OversamplingMode = DISABLE;
  hadc1.Init.Oversampling.Ratio = 1;
  if (HAL_ADC_Init(&hadc1) != HAL_OK)
  {
    Error_Handler();
  }

  /** Configure the ADC multi-mode
  */
  multimode.Mode = ADC_MODE_INDEPENDENT;
  if (HAL_ADCEx_MultiModeConfigChannel(&hadc1, &multimode) != HAL_OK)
  {
    Error_Handler();
  }

  /** Configure Regular Channel
  */
  sConfig.Channel = ADC_CHANNEL_0;
  sConfig.Rank = ADC_REGULAR_RANK_1;
  sConfig.SamplingTime = ADC_SAMPLETIME_32CYCLES_5;
  sConfig.SingleDiff = ADC_SINGLE_ENDED;
  sConfig.OffsetNumber = ADC_OFFSET_NONE;
  sConfig.Offset = 0;
  sConfig.OffsetSignedSaturation = DISABLE;
  if (HAL_ADC_ConfigChannel(&hadc1, &sConfig) != HAL_OK)
  {
    Error_Handler();
  }

  /** Configure Regular Channel
  */
  sConfig.Channel = ADC_CHANNEL_1;
  sConfig.Rank = ADC_REGULAR_RANK_2;
  if (HAL_ADC_ConfigChannel(&hadc1, &sConfig) != HAL_OK)
  {
    Error_Handler();
  }

  /** Configure Regular Channel
  */
  sConfig.Channel = ADC_CHANNEL_16;
  sConfig.Rank = ADC_REGULAR_RANK_3;
  if (HAL_ADC_ConfigChannel(&hadc1, &sConfig) != HAL_OK)
  {
    Error_Handler();
  }

}

static void MX_ADC2_Init(void)
{

  ADC_ChannelConfTypeDef sConfig = {0};

  /** Common config
  */
  hadc2.Instance = ADC2;
  hadc2.Init.ClockPrescaler = ADC_CLOCK_ASYNC_DIV2;
  hadc2.Init.Resolution = ADC_RESOLUTION_16B;
  hadc2.Init.ScanConvMode = ADC_SCAN_ENABLE;
  hadc2.Init.EOCSelection = ADC_EOC_SEQ_CONV;
  hadc2.Init.LowPowerAutoWait = DISABLE;
  hadc2.Init.ContinuousConvMode = DISABLE;
  hadc2.Init.NbrOfConversion = 3;
  hadc2.Init.DiscontinuousConvMode = DISABLE;
  hadc2.Init.ExternalTrigConv = ADC_EXTERNALTRIG_T15_TRGO;
  hadc2.Init.ExternalTrigConvEdge = ADC_EXTERNALTRIGCONVEDGE_RISING;
  hadc2.Init.ConversionDataManagement = ADC_CONVERSIONDATA_DMA_CIRCULAR;
  hadc2.Init.Overrun = ADC_OVR_DATA_PRESERVED;
  hadc2.Init.LeftBitShift = ADC_LEFTBITSHIFT_NONE;
  hadc2.Init.OversamplingMode = DISABLE;
  hadc2.Init.Oversampling.Ratio = 1;
  if (HAL_ADC_Init(&hadc2) != HAL_OK)
  {
    Error_Handler();
  }

  /** Configure Regular Channel
  */
  sConfig.Channel = ADC_CHANNEL_3;
  sConfig.Rank = ADC_REGULAR_RANK_1;
  sConfig.SamplingTime = ADC_SAMPLETIME_32CYCLES_5;
  sConfig.SingleDiff = ADC_SINGLE_ENDED;
  sConfig.OffsetNumber = ADC_OFFSET_NONE;
  sConfig.Offset = 0;
  sConfig.OffsetSignedSaturation = DISABLE;
  if (HAL_ADC_ConfigChannel(&hadc2, &sConfig) != HAL_OK)
  {
    Error_Handler();
  }

  /** Configure Regular Channel
  */
  sConfig.Channel = ADC_CHANNEL_12;
  sConfig.Rank = ADC_REGULAR_RANK_2;
  if (HAL_ADC_ConfigChannel(&hadc2, &sConfig) != HAL_OK)
  {
    Error_Handler();
  }

  /** Configure Regular Channel
  */
  sConfig.Channel = ADC_CHANNEL_13;
  sConfig.Rank = ADC_REGULAR_RANK_3;
  if (HAL_ADC_ConfigChannel(&hadc2, &sConfig) != HAL_OK)
  {
    Error_Handler();
  }

}

static void MX_ADC3_Init(void)
{

  ADC_ChannelConfTypeDef sConfig = {0};

  /* USER CODE BEGIN ADC3_Init 1 */
  hadc3.Init.ClockPrescaler = ADC_CLOCK_ASYNC_DIV2;
  /* USER CODE END ADC3_Init 1 */

  /** Common config
  */
  hadc3.Instance = ADC3;
  hadc3.Init.Resolution = ADC_RESOLUTION_16B;
  hadc3.Init.ScanConvMode = ADC_SCAN_ENABLE;
  hadc3.Init.EOCSelection = ADC_EOC_SEQ_CONV;
  hadc3.Init.LowPowerAutoWait = DISABLE;
  hadc3.Init.ContinuousConvMode = DISABLE;
  hadc3.Init.NbrOfConversion = 4;
  hadc3.Init.DiscontinuousConvMode = DISABLE;
  hadc3.Init.ExternalTrigConv = ADC_EXTERNALTRIG_T15_TRGO;
  hadc3.Init.ExternalTrigConvEdge = ADC_EXTERNALTRIGCONVEDGE_RISING;
  hadc3.Init.ConversionDataManagement = ADC_CONVERSIONDATA_DMA_CIRCULAR;
  hadc3.Init.Overrun = ADC_OVR_DATA_PRESERVED;
  hadc3.Init.LeftBitShift = ADC_LEFTBITSHIFT_NONE;
  hadc3.Init.OversamplingMode = DISABLE;
  hadc3.Init.Oversampling.Ratio = 1;
  if (HAL_ADC_Init(&hadc3) != HAL_OK)
  {
    Error_Handler();
  }

  /** Configure Regular Channel
  */
  sConfig.Channel = ADC_CHANNEL_2;
  sConfig.Rank = ADC_REGULAR_RANK_1;
  sConfig.SamplingTime = ADC_SAMPLETIME_32CYCLES_5;
  sConfig.SingleDiff = ADC_SINGLE_ENDED;
  sConfig.OffsetNumber = ADC_OFFSET_NONE;
  sConfig.Offset = 0;
  sConfig.OffsetSignedSaturation = DISABLE;
  if (HAL_ADC_ConfigChannel(&hadc3, &sConfig) != HAL_OK)
  {
    Error_Handler();
  }

  /** Configure Regular Channel
  */
  sConfig.Channel = ADC_CHANNEL_6;
  sConfig.Rank = ADC_REGULAR_RANK_2;
  if (HAL_ADC_ConfigChannel(&hadc3, &sConfig) != HAL_OK)
  {
    Error_Handler();
  }

  /** Configure Regular Channel
  */
  sConfig.Channel = ADC_CHANNEL_7;
  sConfig.Rank = ADC_REGULAR_RANK_3;
  if (HAL_ADC_ConfigChannel(&hadc3, &sConfig) != HAL_OK)
  {
    Error_Handler();
  }

  /** Configure Regular Channel
  */
  sConfig.Channel = ADC_CHANNEL_8;
  sConfig.Rank = ADC_REGULAR_RANK_4;
  if (HAL_ADC_ConfigChannel(&hadc3, &sConfig) != HAL_OK)
  {
    Error_Handler();
  }

}

static void MX_DAC1_Init(void)
{

  DAC_ChannelConfTypeDef sConfig = {0};

  /** DAC Initialization
  */
  hdac1.Instance = DAC1;
  if (HAL_DAC_Init(&hdac1) != HAL_OK)
  {
    Error_Handler();
  }

  /** DAC channel OUT1 config
  */
  sConfig.DAC_SampleAndHold = DAC_SAMPLEANDHOLD_DISABLE;
  sConfig.DAC_Trigger = DAC_TRIGGER_NONE;
  sConfig.DAC_OutputBuffer = DAC_OUTPUTBUFFER_ENABLE;
  sConfig.DAC_ConnectOnChipPeripheral = DAC_CHIPCONNECT_DISABLE;
  sConfig.DAC_UserTrimming = DAC_TRIMMING_FACTORY;
  if (HAL_DAC_ConfigChannel(&hdac1, &sConfig, DAC_CHANNEL_1) != HAL_OK)
  {
    Error_Handler();
  }

}

static void MX_SPI2_Init(void)
{

  /* SPI2 parameter configuration*/
  hspi2.Instance = SPI2;
  hspi2.Init.Mode = SPI_MODE_MASTER;
  hspi2.Init.Direction = SPI_DIRECTION_2LINES_TXONLY;
  hspi2.Init.DataSize = SPI_DATASIZE_8BIT;
  hspi2.Init.CLKPolarity = SPI_POLARITY_LOW;
  hspi2.Init.CLKPhase = SPI_PHASE_2EDGE;
  hspi2.Init.NSS = SPI_NSS_SOFT;
  hspi2.Init.BaudRatePrescaler = SPI_BAUDRATEPRESCALER_4;
  hspi2.Init.FirstBit = SPI_FIRSTBIT_MSB;
  hspi2.Init.TIMode = SPI_TIMODE_DISABLE;
  hspi2.Init.CRCCalculation = SPI_CRCCALCULATION_DISABLE;
  hspi2.Init.CRCPolynomial = 0x0;
  hspi2.Init.NSSPMode = SPI_NSS_PULSE_ENABLE;
  hspi2.Init.NSSPolarity = SPI_NSS_POLARITY_LOW;
  hspi2.Init.FifoThreshold = SPI_FIFO_THRESHOLD_01DATA;
  hspi2.Init.TxCRCInitializationPattern = SPI_CRC_INITIALIZATION_ALL_ZERO_PATTERN;
  hspi2.Init.RxCRCInitializationPattern = SPI_CRC_INITIALIZATION_ALL_ZERO_PATTERN;
  hspi2.Init.MasterSSIdleness = SPI_MASTER_SS_IDLENESS_00CYCLE;
  hspi2.Init.MasterInterDataIdleness = SPI_MASTER_INTERDATA_IDLENESS_00CYCLE;
  hspi2.Init.MasterReceiverAutoSusp = SPI_MASTER_RX_AUTOSUSP_DISABLE;
  hspi2.Init.MasterKeepIOState = SPI_MASTER_KEEP_IO_STATE_DISABLE;
  hspi2.Init.IOSwap = SPI_IO_SWAP_DISABLE;
  if (HAL_SPI_Init(&hspi2) != HAL_OK)
  {
    Error_Handler();
  }

}

static void MX_TIM1_Init(void)
{

  TIM_ClockConfigTypeDef sClockSourceConfig = {0};
  TIM_MasterConfigTypeDef sMasterConfig = {0};
  TIM_OC_InitTypeDef sConfigOC = {0};
  TIM_BreakDeadTimeConfigTypeDef sBreakDeadTimeConfig = {0};

  htim1.Instance = TIM1;
  htim1.Init.Prescaler = 48000-1;
  htim1.Init.CounterMode = TIM_COUNTERMODE_UP;
  htim1.Init.Period = 10;
  htim1.Init.ClockDivision = TIM_CLOCKDIVISION_DIV1;
  htim1.Init.RepetitionCounter = 0;
  htim1.Init.AutoReloadPreload = TIM_AUTORELOAD_PRELOAD_DISABLE;
  if (HAL_TIM_Base_Init(&htim1) != HAL_OK)
  {
    Error_Handler();
  }
  sClockSourceConfig.ClockSource = TIM_CLOCKSOURCE_INTERNAL;
  if (HAL_TIM_ConfigClockSource(&htim1, &sClockSourceConfig) != HAL_OK)
  {
    Error_Handler();
  }
  if (HAL_TIM_PWM_Init(&htim1) != HAL_OK)
  {
    Error_Handler();
  }
  sMasterConfig.MasterOutputTrigger = TIM_TRGO_RESET;
  sMasterConfig.MasterOutputTrigger2 = TIM_TRGO2_RESET;
  sMasterConfig.MasterSlaveMode = TIM_MASTERSLAVEMODE_DISABLE;
  if (HAL_TIMEx_MasterConfigSynchronization(&htim1, &sMasterConfig) != HAL_OK)
  {
    Error_Handler();
  }
  sConfigOC.OCMode = TIM_OCMODE_PWM2;
  sConfigOC.Pulse = 1;
  sConfigOC.OCPolarity = TIM_OCPOLARITY_HIGH;
  sConfigOC.OCNPolarity = TIM_OCNPOLARITY_HIGH;
  sConfigOC.OCFastMode = TIM_OCFAST_DISABLE;
  sConfigOC.OCIdleState = TIM_OCIDLESTATE_RESET;
  sConfigOC.OCNIdleState = TIM_OCNIDLESTATE_RESET;
  if (HAL_TIM_PWM_ConfigChannel(&htim1, &sConfigOC, TIM_CHANNEL_1) != HAL_OK)
  {
    Error_Handler();
  }
  sBreakDeadTimeConfig.OffStateRunMode = TIM_OSSR_DISABLE;
  sBreakDeadTimeConfig.OffStateIDLEMode = TIM_OSSI_DISABLE;
  sBreakDeadTimeConfig.LockLevel = TIM_LOCKLEVEL_OFF;
  sBreakDeadTimeConfig.DeadTime = 0;
  sBreakDeadTimeConfig.BreakState = TIM_BREAK_DISABLE;
  sBreakDeadTimeConfig.BreakPolarity = TIM_BREAKPOLARITY_HIGH;
  sBreakDeadTimeConfig.BreakFilter = 0;
  sBreakDeadTimeConfig.Break2State = TIM_BREAK2_DISABLE;
  sBreakDeadTimeConfig.Break2Polarity = TIM_BREAK2POLARITY_HIGH;
  sBreakDeadTimeConfig.Break2Filter = 0;
  sBreakDeadTimeConfig.AutomaticOutput = TIM_AUTOMATICOUTPUT_DISABLE;
  if (HAL_TIMEx_ConfigBreakDeadTime(&htim1, &sBreakDeadTimeConfig) != HAL_OK)
  {
    Error_Handler();
  }
  HAL_TIM_MspPostInit(&htim1);

}

static void MX_TIM2_Init(void)
{

  TIM_ClockConfigTypeDef sClockSourceConfig = {0};
  TIM_MasterConfigTypeDef sMasterConfig = {0};
  TIM_OC_InitTypeDef sConfigOC = {0};

  htim2.Instance = TIM2;
  htim2.Init.Prescaler = 100-1;
  htim2.Init.CounterMode = TIM_COUNTERMODE_UP;
  htim2.Init.Period = 4294967295;
  htim2.Init.ClockDivision = TIM_CLOCKDIVISION_DIV1;
  htim2.Init.AutoReloadPreload = TIM_AUTORELOAD_PRELOAD_DISABLE;
  if (HAL_TIM_Base_Init(&htim2) != HAL_OK)
  {
    Error_Handler();
  }
  sClockSourceConfig.ClockSource = TIM_CLOCKSOURCE_INTERNAL;
  if (HAL_TIM_ConfigClockSource(&htim2, &sClockSourceConfig) != HAL_OK)
  {
    Error_Handler();
  }
  if (HAL_TIM_PWM_Init(&htim2) != HAL_OK)
  {
    Error_Handler();
  }
  sMasterConfig.MasterOutputTrigger = TIM_TRGO_RESET;
  sMasterConfig.MasterSlaveMode = TIM_MASTERSLAVEMODE_DISABLE;
  if (HAL_TIMEx_MasterConfigSynchronization(&htim2, &sMasterConfig) != HAL_OK)
  {
    Error_Handler();
  }
  sConfigOC.OCMode = TIM_OCMODE_PWM1;
  sConfigOC.Pulse = 0;
  sConfigOC.OCPolarity = TIM_OCPOLARITY_HIGH;
  sConfigOC.OCFastMode = TIM_OCFAST_DISABLE;
  if (HAL_TIM_PWM_ConfigChannel(&htim2, &sConfigOC, TIM_CHANNEL_2) != HAL_OK)
  {
    Error_Handler();
  }
  HAL_TIM_MspPostInit(&htim2);

}

static void MX_TIM3_Init(void)
{

  TIM_ClockConfigTypeDef sClockSourceConfig = {0};
  TIM_MasterConfigTypeDef sMasterConfig = {0};

  htim3.Instance = TIM3;
  htim3.Init.Prescaler = 0;
  htim3.Init.CounterMode = TIM_COUNTERMODE_UP;
  htim3.Init.Period = 15625;
  htim3.Init.ClockDivision = TIM_CLOCKDIVISION_DIV1;
  htim3.Init.AutoReloadPreload = TIM_AUTORELOAD_PRELOAD_DISABLE;
  if (HAL_TIM_Base_Init(&htim3) != HAL_OK)
  {
    Error_Handler();
  }
  sClockSourceConfig.ClockSource = TIM_CLOCKSOURCE_INTERNAL;
  if (HAL_TIM_ConfigClockSource(&htim3, &sClockSourceConfig) != HAL_OK)
  {
    Error_Handler();
  }
  sMasterConfig.MasterOutputTrigger = TIM_TRGO_RESET;
  sMasterConfig.MasterSlaveMode = TIM_MASTERSLAVEMODE_DISABLE;
  if (HAL_TIMEx_MasterConfigSynchronization(&htim3, &sMasterConfig) != HAL_OK)
  {
    Error_Handler();
  }

}

static void MX_TIM4_Init(void)
{

  TIM_MasterConfigTypeDef sMasterConfig = {0};
  TIM_IC_InitTypeDef sConfigIC = {0};

  htim4.Instance = TIM4;
  htim4.Init.Prescaler = 0;
  htim4.Init.CounterMode = TIM_COUNTERMODE_UP;
  htim4.Init.Period = 65535;
  htim4.Init.ClockDivision = TIM_CLOCKDIVISION_DIV1;
  htim4.Init.AutoReloadPreload = TIM_AUTORELOAD_PRELOAD_DISABLE;
  if (HAL_TIM_IC_Init(&htim4) != HAL_OK)
  {
    Error_Handler();
  }
  sMasterConfig.MasterOutputTrigger = TIM_TRGO_RESET;
  sMasterConfig.MasterSlaveMode = TIM_MASTERSLAVEMODE_DISABLE;
  if (HAL_TIMEx_MasterConfigSynchronization(&htim4, &sMasterConfig) != HAL_OK)
  {
    Error_Handler();
  }
  sConfigIC.ICPolarity = TIM_INPUTCHANNELPOLARITY_RISING;
  sConfigIC.ICSelection = TIM_ICSELECTION_DIRECTTI;
  sConfigIC.ICPrescaler = TIM_ICPSC_DIV1;
  sConfigIC.ICFilter = 0;
  if (HAL_TIM_IC_ConfigChannel(&htim4, &sConfigIC, TIM_CHANNEL_4) != HAL_OK)
  {
    Error_Handler();
  }

}

static void MX_TIM8_Init(void)
{

  TIM_MasterConfigTypeDef sMasterConfig = {0};
  TIM_OC_InitTypeDef sConfigOC = {0};
  TIM_BreakDeadTimeConfigTypeDef sBreakDeadTimeConfig = {0};

  htim8.Instance = TIM8;
  htim8.Init.Prescaler = 0;
  htim8.Init.CounterMode = TIM_COUNTERMODE_UP;
  htim8.Init.Period = 65535;
  htim8.Init.ClockDivision = TIM_CLOCKDIVISION_DIV1;
  htim8.Init.RepetitionCounter = 0;
  htim8.Init.AutoReloadPreload = TIM_AUTORELOAD_PRELOAD_DISABLE;
  if (HAL_TIM_PWM_Init(&htim8) != HAL_OK)
  {
    Error_Handler();
  }
  sMasterConfig.MasterOutputTrigger = TIM_TRGO_RESET;
  sMasterConfig.MasterOutputTrigger2 = TIM_TRGO2_RESET;
  sMasterConfig.MasterSlaveMode = TIM_MASTERSLAVEMODE_DISABLE;
  if (HAL_TIMEx_MasterConfigSynchronization(&htim8, &sMasterConfig) != HAL_OK)
  {
    Error_Handler();
  }
  sConfigOC.OCMode = TIM_OCMODE_PWM1;
  sConfigOC.Pulse = 0;
  sConfigOC.OCPolarity = TIM_OCPOLARITY_HIGH;
  sConfigOC.OCNPolarity = TIM_OCNPOLARITY_HIGH;
  sConfigOC.OCFastMode = TIM_OCFAST_DISABLE;
  sConfigOC.OCIdleState = TIM_OCIDLESTATE_RESET;
  sConfigOC.OCNIdleState = TIM_OCNIDLESTATE_RESET;
  if (HAL_TIM_PWM_ConfigChannel(&htim8, &sConfigOC, TIM_CHANNEL_3) != HAL_OK)
  {
    Error_Handler();
  }
  sBreakDeadTimeConfig.OffStateRunMode = TIM_OSSR_DISABLE;
  sBreakDeadTimeConfig.OffStateIDLEMode = TIM_OSSI_DISABLE;
  sBreakDeadTimeConfig.LockLevel = TIM_LOCKLEVEL_OFF;
  sBreakDeadTimeConfig.DeadTime = 0;
  sBreakDeadTimeConfig.BreakState = TIM_BREAK_DISABLE;
  sBreakDeadTimeConfig.BreakPolarity = TIM_BREAKPOLARITY_HIGH;
  sBreakDeadTimeConfig.BreakFilter = 0;
  sBreakDeadTimeConfig.Break2State = TIM_BREAK2_DISABLE;
  sBreakDeadTimeConfig.Break2Polarity = TIM_BREAK2POLARITY_HIGH;
  sBreakDeadTimeConfig.Break2Filter = 0;
  sBreakDeadTimeConfig.AutomaticOutput = TIM_AUTOMATICOUTPUT_DISABLE;
  if (HAL_TIMEx_ConfigBreakDeadTime(&htim8, &sBreakDeadTimeConfig) != HAL_OK)
  {
    Error_Handler();
  }
  HAL_TIM_MspPostInit(&htim8);

}

static void MX_TIM15_Init(void)
{

  TIM_ClockConfigTypeDef sClockSourceConfig = {0};
  TIM_MasterConfigTypeDef sMasterConfig = {0};

  htim15.Instance = TIM15;
  htim15.Init.Prescaler = 0;
  htim15.Init.CounterMode = TIM_COUNTERMODE_UP;
  htim15.Init.Period = 13019;
  htim15.Init.ClockDivision = TIM_CLOCKDIVISION_DIV1;
  htim15.Init.RepetitionCounter = 0;
  htim15.Init.AutoReloadPreload = TIM_AUTORELOAD_PRELOAD_ENABLE;
  if (HAL_TIM_Base_Init(&htim15) != HAL_OK)
  {
    Error_Handler();
  }
  sClockSourceConfig.ClockSource = TIM_CLOCKSOURCE_INTERNAL;
  if (HAL_TIM_ConfigClockSource(&htim15, &sClockSourceConfig) != HAL_OK)
  {
    Error_Handler();
  }
  sMasterConfig.MasterOutputTrigger = TIM_TRGO_UPDATE;
  sMasterConfig.MasterSlaveMode = TIM_MASTERSLAVEMODE_DISABLE;
  if (HAL_TIMEx_MasterConfigSynchronization(&htim15, &sMasterConfig) != HAL_OK)
  {
    Error_Handler();
  }

}

static void MX_USART1_UART_Init(void)
{

  huart1.Instance = USART1;
  huart1.Init.BaudRate = 115200;
  huart1.Init.WordLength = UART_WORDLENGTH_8B;
  huart1.Init.StopBits = UART_STOPBITS_1;
  huart1.Init.Parity = UART_PARITY_NONE;
  huart1.Init.Mode = UART_MODE_TX_RX;
  huart1.Init.HwFlowCtl = UART_HWCONTROL_NONE;
  huart1.Init.OverSampling = UART_OVERSAMPLING_16;
  huart1.Init.OneBitSampling = UART_ONE_BIT_SAMPLE_DISABLE;
  huart1.Init.ClockPrescaler = UART_PRESCALER_DIV1;
  huart1.AdvancedInit.AdvFeatureInit = UART_ADVFEATURE_NO_INIT;
  if (HAL_UART_Init(&huart1) != HAL_OK)
  {
    Error_Handler();
  }
  if (HAL_UARTEx_SetTxFifoThreshold(&huart1, UART_TXFIFO_THRESHOLD_1_8) != HAL_OK)
  {
    Error_Handler();
  }
  if (HAL_UARTEx_SetRxFifoThreshold(&huart1, UART_RXFIFO_THRESHOLD_1_8) != HAL_OK)
  {
    Error_Handler();
  }
  if (HAL_UARTEx_DisableFifoMode(&huart1) != HAL_OK)
  {
    Error_Handler();
  }

}

static void MX_USB_OTG_HS_PCD_Init(void)
{

  hpcd_USB_OTG_HS.Instance = USB_OTG_HS;
  hpcd_USB_OTG_HS.Init.dev_endpoints = 9;
  hpcd_USB_OTG_HS.Init.speed = PCD_SPEED_HIGH;
  hpcd_USB_OTG_HS.Init.dma_enable = ENABLE;
  hpcd_USB_OTG_HS.Init.phy_itface = USB_OTG_ULPI_PHY;
  hpcd_USB_OTG_HS.Init.Sof_enable = ENABLE;
  hpcd_USB_OTG_HS.Init.low_power_enable = DISABLE;
  hpcd_USB_OTG_HS.Init.lpm_enable = DISABLE;
  hpcd_USB_OTG_HS.Init.vbus_sensing_enable = DISABLE;
  hpcd_USB_OTG_HS.Init.use_dedicated_ep1 = DISABLE;
  hpcd_USB_OTG_HS.Init.use_external_vbus = DISABLE;
  if (HAL_PCD_Init(&hpcd_USB_OTG_HS) != HAL_OK)
  {
    Error_Handler();
  }

}

static void MX_DMA_Init(void)
{

  /* DMA controller clock enable */
  __HAL_RCC_DMA1_CLK_ENABLE();
  __HAL_RCC_DMA2_CLK_ENABLE();

  /* DMA interrupt init */
  /* DMA1_Stream0_IRQn interrupt configuration */
  HAL_NVIC_SetPriority(DMA1_Stream0_IRQn, 5, 0);
  HAL_NVIC_EnableIRQ(DMA1_Stream0_IRQn);
  /* DMA1_Stream1_IRQn interrupt configuration */
  HAL_NVIC_SetPriority(DMA1_Stream1_IRQn, 5, 0);
  HAL_NVIC_EnableIRQ(DMA1_Stream1_IRQn);
  /* DMA1_Stream2_IRQn interrupt configuration */
  HAL_NVIC_SetPriority(DMA1_Stream2_IRQn, 5, 0);
  HAL_NVIC_EnableIRQ(DMA1_Stream2_IRQn);
  /* DMA1_Stream3_IRQn interrupt configuration */
  HAL_NVIC_SetPriority(DMA1_Stream3_IRQn, 5, 0);
  HAL_NVIC_EnableIRQ(DMA1_Stream3_IRQn);
  /* DMA2_Stream2_IRQn interrupt configuration */
  HAL_NVIC_SetPriority(DMA2_Stream2_IRQn, 5, 0);
  HAL_NVIC_EnableIRQ(DMA2_Stream2_IRQn);

}

/* FMC initialization function */
void MX_FMC_Init(void)
{

  FMC_SDRAM_TimingTypeDef SdramTiming = {0};

  /** Perform the SDRAM1 memory initialization sequence
  */
  hsdram1.Instance = FMC_SDRAM_DEVICE;
  /* hsdram1.Init */
  hsdram1.Init.SDBank = FMC_SDRAM_BANK2;
  hsdram1.Init.ColumnBitsNumber = FMC_SDRAM_COLUMN_BITS_NUM_9;
  hsdram1.Init.RowBitsNumber = FMC_SDRAM_ROW_BITS_NUM_12;
  hsdram1.Init.MemoryDataWidth = FMC_SDRAM_MEM_BUS_WIDTH_32;
  hsdram1.Init.InternalBankNumber = FMC_SDRAM_INTERN_BANKS_NUM_4;
  hsdram1.Init.CASLatency = FMC_SDRAM_CAS_LATENCY_3;
  hsdram1.Init.WriteProtection = FMC_SDRAM_WRITE_PROTECTION_DISABLE;
  hsdram1.Init.SDClockPeriod = FMC_SDRAM_CLOCK_PERIOD_2;
  hsdram1.Init.ReadBurst = FMC_SDRAM_RBURST_ENABLE;
  hsdram1.Init.ReadPipeDelay = FMC_SDRAM_RPIPE_DELAY_0;
  /* SdramTiming */
  SdramTiming.LoadToActiveDelay = 2;
  SdramTiming.ExitSelfRefreshDelay = 7;
  SdramTiming.SelfRefreshTime = 4;
  SdramTiming.RowCycleDelay = 6;
  SdramTiming.WriteRecoveryTime = 2;
  SdramTiming.RPDelay = 2;
  SdramTiming.RCDDelay = 2;

  if (HAL_SDRAM_Init(&hsdram1, &SdramTiming) != HAL_OK)
  {
    Error_Handler( );
  }

}

static void MX_GPIO_Init(void)
{
  GPIO_InitTypeDef GPIO_InitStruct = {0};

  /* GPIO Ports Clock Enable */
  __HAL_RCC_GPIOI_CLK_ENABLE();
  __HAL_RCC_GPIOB_CLK_ENABLE();
  __HAL_RCC_GPIOE_CLK_ENABLE();
  __HAL_RCC_GPIOG_CLK_ENABLE();
  __HAL_RCC_GPIOD_CLK_ENABLE();
  __HAL_RCC_GPIOA_CLK_ENABLE();
  __HAL_RCC_GPIOH_CLK_ENABLE();
  __HAL_RCC_GPIOC_CLK_ENABLE();
  __HAL_RCC_GPIOF_CLK_ENABLE();
  __HAL_RCC_GPIOK_CLK_ENABLE();

  /*Configure GPIO pin Output Level */
  HAL_GPIO_WritePin(DAC8562_SPI_SYNC_GPIO_Port, DAC8562_SPI_SYNC_Pin, GPIO_PIN_RESET);

  /*Configure GPIO pin Output Level */
  HAL_GPIO_WritePin(GPIOI, LED1_Pin|GPIO_PIN_13|LED3_Pin, GPIO_PIN_RESET);

  /*Configure GPIO pin : DAC8562_SPI_SYNC_Pin */
  GPIO_InitStruct.Pin = DAC8562_SPI_SYNC_Pin;
  GPIO_InitStruct.Mode = GPIO_MODE_OUTPUT_PP;
  GPIO_InitStruct.Pull = GPIO_NOPULL;
  GPIO_InitStruct.Speed = GPIO_SPEED_FREQ_VERY_HIGH;
  HAL_GPIO_Init(DAC8562_SPI_SYNC_GPIO_Port, &GPIO_InitStruct);

  /*Configure GPIO pins : LED1_Pin PI13 LED3_Pin */
  GPIO_InitStruct.Pin = LED1_Pin|GPIO_PIN_13|LED3_Pin;
  GPIO_InitStruct.Mode = GPIO_MODE_OUTPUT_PP;
  GPIO_InitStruct.Pull = GPIO_NOPULL;
  GPIO_InitStruct.Speed = GPIO_SPEED_FREQ_LOW;
  HAL_GPIO_Init(GPIOI, &GPIO_InitStruct);

}

void StartDefaultTask(void *argument)
{
  /* init code for LWIP */
  MX_LWIP_Init();
  /* USER CODE BEGIN 5 */
  osDelay(2000);
  IEC61850_SVHandle = osThreadNew(IEC61850_SV_Task, NULL, &IEC61850_SV_attributes);

  /* Infinite loop */
    apMain();
  /* USER CODE END 5 */
}

 /* MPU Configuration */

void MPU_Config(void)
{
  MPU_Region_InitTypeDef MPU_InitStruct = {0};

  /* Disables the MPU */
  HAL_MPU_Disable();

  /** Initializes and configures the Region and the memory to be protected
  */
  MPU_InitStruct.Enable = MPU_REGION_ENABLE;
  MPU_InitStruct.Number = MPU_REGION_NUMBER0;
  MPU_InitStruct.BaseAddress = 0x0;
  MPU_InitStruct.Size = MPU_REGION_SIZE_4GB;
  MPU_InitStruct.SubRegionDisable = 0x87;
  MPU_InitStruct.TypeExtField = MPU_TEX_LEVEL0;
  MPU_InitStruct.AccessPermission = MPU_REGION_NO_ACCESS;
  MPU_InitStruct.DisableExec = MPU_INSTRUCTION_ACCESS_DISABLE;
  MPU_InitStruct.IsShareable = MPU_ACCESS_SHAREABLE;
  MPU_InitStruct.IsCacheable = MPU_ACCESS_NOT_CACHEABLE;
  MPU_InitStruct.IsBufferable = MPU_ACCESS_NOT_BUFFERABLE;

  HAL_MPU_ConfigRegion(&MPU_InitStruct);

  /** Initializes and configures the Region and the memory to be protected
  */
  MPU_InitStruct.Number = MPU_REGION_NUMBER1;
  MPU_InitStruct.BaseAddress = 0x030000600;
  MPU_InitStruct.Size = MPU_REGION_SIZE_128KB;
  MPU_InitStruct.SubRegionDisable = 0x0;
  MPU_InitStruct.TypeExtField = MPU_TEX_LEVEL1;
  MPU_InitStruct.AccessPermission = MPU_REGION_FULL_ACCESS;
  MPU_InitStruct.IsShareable = MPU_ACCESS_NOT_SHAREABLE;

  HAL_MPU_ConfigRegion(&MPU_InitStruct);

  /** Initializes and configures the Region and the memory to be protected
  */
  MPU_InitStruct.Number = MPU_REGION_NUMBER2;
  MPU_InitStruct.BaseAddress = 0x30000000;
  MPU_InitStruct.Size = MPU_REGION_SIZE_512B;
  MPU_InitStruct.TypeExtField = MPU_TEX_LEVEL0;
  MPU_InitStruct.IsShareable = MPU_ACCESS_SHAREABLE;
  MPU_InitStruct.IsBufferable = MPU_ACCESS_BUFFERABLE;

  HAL_MPU_ConfigRegion(&MPU_InitStruct);

  /** Initializes and configures the Region and the memory to be protected
  */
  MPU_InitStruct.Number = MPU_REGION_NUMBER3;
  MPU_InitStruct.BaseAddress = 0x38000000;
  MPU_InitStruct.Size = MPU_REGION_SIZE_64KB;
  MPU_InitStruct.DisableExec = MPU_INSTRUCTION_ACCESS_ENABLE;
  MPU_InitStruct.IsBufferable = MPU_ACCESS_NOT_BUFFERABLE;

  HAL_MPU_ConfigRegion(&MPU_InitStruct);

  /** Initializes and configures the Region and the memory to be protected
  */
  MPU_InitStruct.Number = MPU_REGION_NUMBER4;
  MPU_InitStruct.BaseAddress = 0xD0000000;
  MPU_InitStruct.Size = MPU_REGION_SIZE_32MB;
  MPU_InitStruct.IsShareable = MPU_ACCESS_NOT_SHAREABLE;
  MPU_InitStruct.IsCacheable = MPU_ACCESS_CACHEABLE;
  MPU_InitStruct.IsBufferable = MPU_ACCESS_BUFFERABLE;

  HAL_MPU_ConfigRegion(&MPU_InitStruct);
  /* Enables the MPU */
  HAL_MPU_Enable(MPU_PRIVILEGED_DEFAULT);

}

void HAL_TIM_PeriodElapsedCallback(TIM_HandleTypeDef *htim)
{
  if (htim->Instance == TIM6)
  {
    HAL_IncTick();
  }
}

void Error_Handler(void)
{
  __disable_irq();
  while (1)
  {
  }
}

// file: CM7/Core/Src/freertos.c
/* USER CODE BEGIN Header */
/**
  ******************************************************************************
  * File Name          : freertos.c
  * Description        : Code for freertos applications
  ******************************************************************************
  * @attention
  *
  * Copyright (c) 2026 STMicroelectronics.
  * All rights reserved.
  *
  * This software is licensed under terms that can be found in the LICENSE file
  * in the root directory of this software component.
  * If no LICENSE file comes with this software, it is provided AS-IS.
  *
  ******************************************************************************
  */
/* USER CODE END Header */

#include "FreeRTOS.h"
#include "task.h"
#include "main.h"

/* USER CODE BEGIN Includes */
#include "stdio.h"
/* USER CODE END Includes */

/* Hook prototypes */
void vApplicationStackOverflowHook(xTaskHandle xTask, char *pcTaskName);

/* USER CODE BEGIN 4 */
void vApplicationStackOverflowHook(xTaskHandle xTask, char *pcTaskName)
{
   /* Run time stack overflow checking is performed if
   configCHECK_FOR_STACK_OVERFLOW is defined to 1 or 2. This hook function is
   called if a stack overflow is detected. */
   printf("Stack overflow in task : %s\r\n", pcTaskName);
}
/* USER CODE END 4 */
